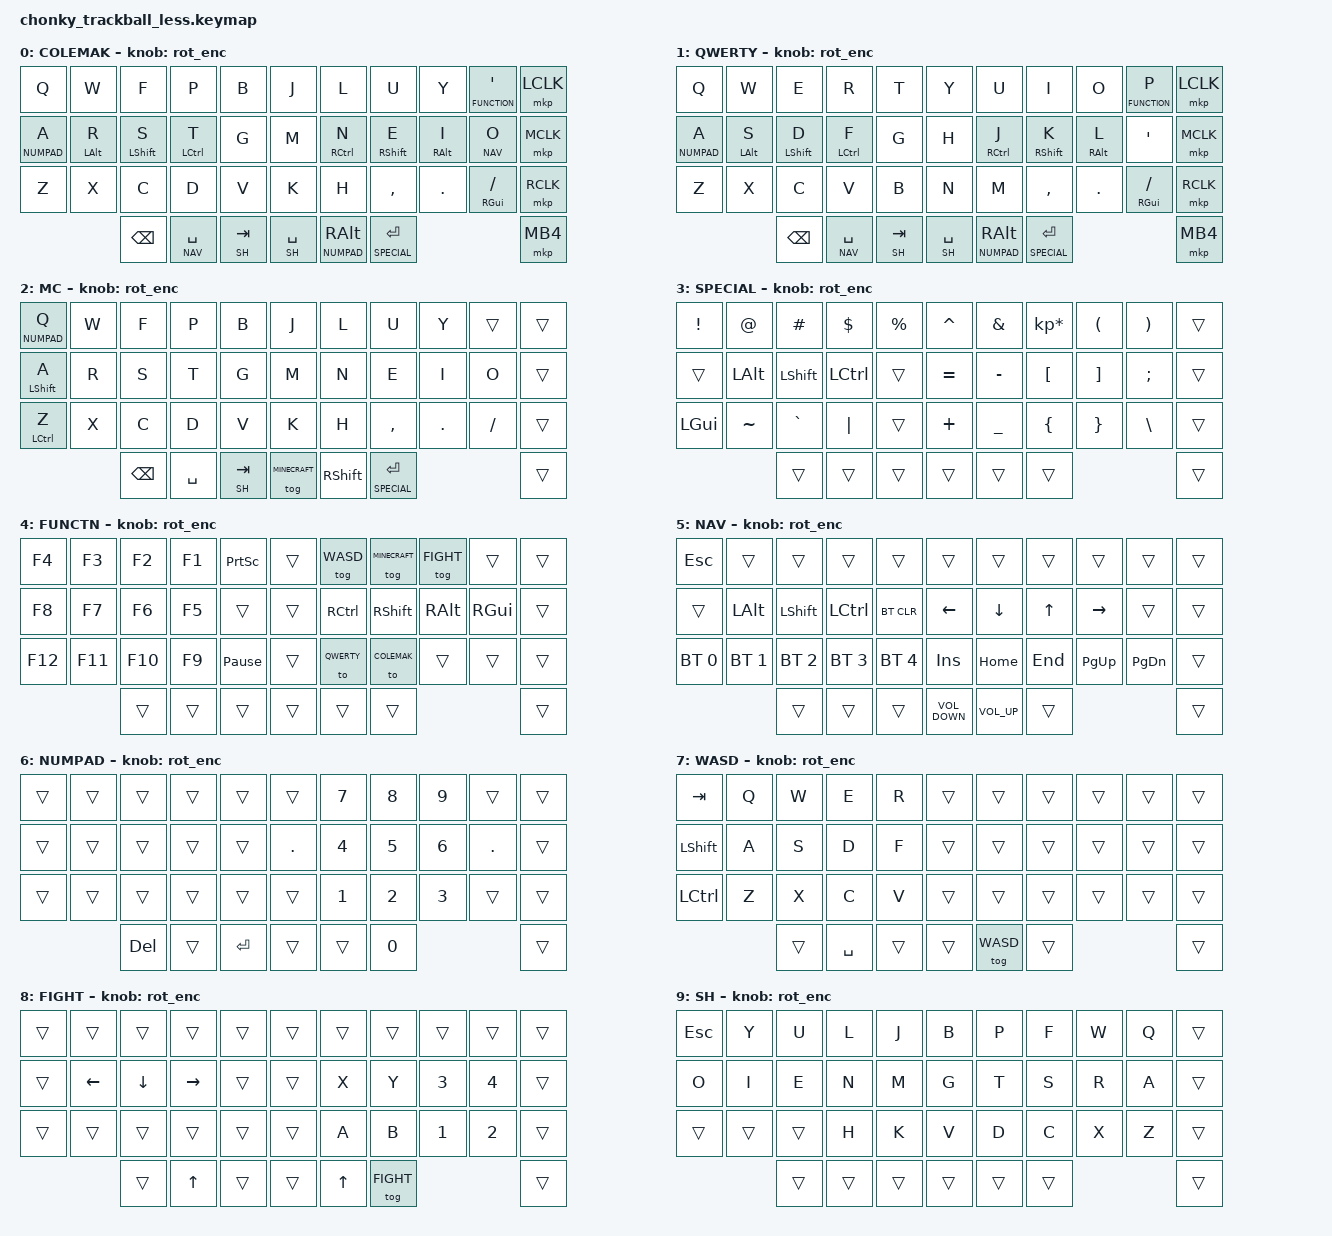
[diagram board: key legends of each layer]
 /*
 * Copyright (c) 2020 The ZMK Contributors
 *
 * SPDX-License-Identifier: MIT
 */


#include <zephyr/dt-bindings/input/input-event-codes.h>

#include <behaviors.dtsi>
#include <behaviors/mouse_keys.dtsi>
#include <behaviors/mouse_key_press.dtsi>
#include <dt-bindings/zmk/keys.h>
#include <dt-bindings/zmk/bt.h>
#include <dt-bindings/zmk/mouse.h>
#include <dt-bindings/zmk/input_transform.h>

#define COLEMAK 0
#define QWERTY 1
#define MINECRAFT 2
#define SPECIAL 3
#define FUNCTION 4
#define NAV 5
#define NUMPAD 6
#define WASD 7
#define FIGHT 8
#define SH 9

&caps_word {
        continue-list = <UNDERSCORE MINUS>;
};

/ {
        xy_transf: xy_transf {
                compatible = "zmk,input-processor-transform";
                #input-processor-cells = <1>;
                type = <INPUT_EV_REL>;
                x-codes = <INPUT_REL_X>, <INPUT_REL_WHEEL>;
                y-codes = <INPUT_REL_Y>, <INPUT_REL_HWHEEL>;
        };
        xy_scaler: xy_scaler {
                compatible = "zmk,input-processor-scaler";
                #input-processor-cells = <2>;
                type = <INPUT_EV_REL>;
                codes = <INPUT_REL_X>, <INPUT_REL_Y>;
                track-remainders;
        };
        x_scaler: x_scaler {
                compatible = "zmk,input-processor-scaler";
                #input-processor-cells = <2>;
                type = <INPUT_EV_REL>;
                codes = <INPUT_REL_X>;
        };
        to_wheel: to_wheel {
                compatible = "zmk,input-processor-code-mapper";
                #input-processor-cells = <0>;
                type = <INPUT_EV_REL>;
                map = <INPUT_REL_X INPUT_REL_MISC>, <INPUT_REL_Y INPUT_REL_WHEEL>;
        };

        //mou0_mmv_il {
        //        compatible = "zmk,input-listener";
        //        device = <&pd>;
        //        input-processors = <&xy_transf (INPUT_TRANSFORM_X_INVERT | INPUT_TRANSFORM_Y_INVERT)>;
        //};

        behaviors {
                combos {
                        compatible = "zmk,combos";
                        combo_caps_word {
                                timeout-ms = <50>;
                                key-positions = <26 27>;
                                bindings = <&caps_word>;
                        };
                };
                lh_ctrl: left_hand_control {
                        compatible = "zmk,behavior-hold-tap";
                        label = "POSITIONAL_HOLD_TAP_LEFT_CONTROL";
                        #binding-cells = <2>;
                        flavor = "balanced";
                        tapping-term-ms = <250>;
                        quick-tap-ms = <300>;
                        bindings = <&kp>, <&kp>;
                        #hold-trigger-key-positions = <1 2 3 12 13 14 15 19 25 26>;
                };
                rh_ctrl: right_hand_control {
                        compatible = "zmk,behavior-hold-tap";
                        label = "POSITIONAL_HOLD_TAP_RIGHT_CONTROL";
                        #binding-cells = <2>;
                        flavor = "balanced";
                        tapping-term-ms = <250>;
                        quick-tap-ms = <300>;
                        bindings = <&kp>, <&kp>;
                        #hold-trigger-key-positions = <3 4 13 14 16 17 25 26 27 29>;
                };
                lh_alt: left_hand_alt {
                        compatible = "zmk,behavior-hold-tap";
                        label = "POSITIONAL_HOLD_TAP_LEFT_ALT";
                        #binding-cells = <2>;
                        flavor = "balanced";
                        tapping-term-ms = <250>;
                        quick-tap-ms = <300>;
                        bindings = <&kp>, <&kp>;
                        #hold-trigger-key-positions = <12 28>;
                };
                rh_alt: right_hand_alt {
                        compatible = "zmk,behavior-hold-tap";
                        label = "POSITIONAL_HOLD_TAP_RIGHT_ALT";
                        #binding-cells = <2>;
                        flavor = "balanced";
                        tapping-term-ms = <250>;
                        quick-tap-ms = <300>;
                        bindings = <&kp>, <&kp>;
                        hold-trigger-key-positions = <12 28>;
                };
                lh_shft: left_hand_shift {
                        compatible = "zmk,behavior-hold-tap";
                        label = "POSITIONAL_HOLD_TAP_LEFT_SHIFT";
                        #binding-cells = <2>;
                        flavor = "balanced";
                        tapping-term-ms = <175>;
                        quick-tap-ms = <300>;
                        bindings = <&kp>, <&kp>;
                };
                rh_shft: right_hand_shift {
                        compatible = "zmk,behavior-hold-tap";
                        label = "POSITIONAL_HOLD_TAP_RIGHT_SHIFT";
                        #binding-cells = <2>;
                        flavor = "balanced";
                        tapping-term-ms = <175>;
                        quick-tap-ms = <300>;
                        bindings = <&kp>, <&kp>;
                };
                lh_num: left_hand_numpad {
                        compatible = "zmk,behavior-hold-tap";
                        label = "POSITIONAL_HOLD_TAP_LEFT_GUI";
                        #binding-cells = <2>;
                        flavor = "balanced";
                        tapping-term-ms = <200>;
                        quick-tap-ms = <300>;
                        bindings = <&kp>, <&kp>;
                };
                rh_gui: right_hand_gui {
                        compatible = "zmk,behavior-hold-tap";
                        label = "POSITIONAL_HOLD_TAP_RIGHT_GUI";
                        #binding-cells = <2>;
                        flavor = "balanced";
                        tapping-term-ms = <250>;
                        quick-tap-ms = <300>;
                        bindings = <&kp>, <&kp>;
                        #hold-trigger-key-positions = <7 12 14>;
                };
                spc_nav: space_navigation {
                        compatible = "zmk,behavior-hold-tap";
                        label = "POSITIONAL_HOLD_TAP_SPACE_NAV";
                        #binding-cells = <2>;
                        flavor = "balanced";
                        tapping-term-ms = <200>;
                        quick-tap-ms = <100>;
                        bindings = <&kp>, <&kp>;
                };
                spc_ret: special_return {
                        compatible = "zmk,behavior-hold-tap";
                        label = "POSITIONAL_HOLD_TAP_SPECIAL_RET";
                        #binding-cells = <2>;
                        flavor = "balanced";
                        tapping-term-ms = <175>;
                        quick-tap-ms = <100>;
                        bindings = <&kp>, <&kp>;
                };
                ec_s: mouse_scroll {
                        compatible = "zmk,behavior-input-two-axis";
                        #binding-cells = <1>;
                        trigger-period-ms = <12>; // slow down for OTA, default is 3ms
                        x-input-code = <INPUT_REL_HWHEEL>;
                        y-input-code = <INPUT_REL_WHEEL>;
                        time-to-max-speed-ms = <177>;
                        acceleration-exponent = <0>;
                };
                rot_enc: rot_enc {
                        compatible = "zmk,behavior-sensor-rotate";
                        #sensor-binding-cells = <0>;
                        bindings = <&ec_s MOVE_Y(-37)>, <&ec_s MOVE_Y(37)>;
                        //bindings = <&msc SCRL_UP>, <&msc SCRL_DOWN>;
                        //bindings = <&kp X>, <&msc SCRL_DOWN>;
                        tap-ms = <65>;
                };

        };
        keymap {
                compatible = "zmk,keymap";

                default_layer {
                        display-name = "COLEMAK";
// |-------------------------------------------------------------------------| |------------------------------------------------------------------------------| |--------|//
// | Q           | W            | F              | P              | B        | | J           | L               | U              | Y            | '"           | | LClick |//
// | A-NUM       | R-alt        | S-shift        | T-ctrl         | G        | | M           | N-ctrl          | E-shift        | I-alt        | O            | | MClick |//
// | Z           | X            | C              | D              | V        | | K           | H               | ,<             | .>           | /?gui        | | RClick |//
// |                            \ BACKSPACE      | SPC (nav)      | TAB-SH   | | SPACE-SH    | RALT-NUM        | ENT (special)  /                             | | Back   |//
// |=========================================================================| |==============================================================================| |--------|//
                        bindings = <
    &kp Q        &kp W          &kp F            &kp P            &kp B         &kp J        &kp L            &kp U            &kp Y          &lt FUNCTION SQT   &mkp LCLK
    &lt NUMPAD A &lh_alt LALT R &lh_shft LSHFT S &lh_ctrl LCTRL T &kp G         &kp M        &rh_ctrl RCTRL N &rh_shft RSHFT E &rh_alt RALT I &lt NAV O          &mkp MCLK
    &kp Z        &kp X          &kp C            &kp D            &kp V         &kp K        &kp H            &kp COMMA        &kp DOT        &rh_gui RGUI FSLH  &mkp RCLK
                                &kp BKSP         &lt NAV SPACE    &lt SH TAB    &lt SH SPACE &lt NUMPAD RALT  &lt SPECIAL RET                                    &mkp MB4
                        >;
                        sensor-bindings = <&rot_enc>;
                };

                qwerty_layer {
                        display-name = "QWERTY";
// |-------------------------------------------------------------------------| |------------------------------------------------------------------------------| |--------|//
// | Q           | W            | E              | R              | T        | | Y           | U              | I              | O            | P             | | LClick |//
// | A-NUM       | S-alt        | D-shift        | F-ctrl         | G        | | H           | J-ctrl         | K-shift        | L-alt        | ;:            | | MClick |//
// | Z           | X            | C              | V              | B        | | N           | M              | ,<             | .>           | /?gui         | | RClick |//
// |                            \ BACKSPACE      | SPC (nav)      | TAB      | |             |                | ENT (special)  /                              | | Back   |//
// |=========================================================================| |==============================================================================| |--------|//
                        bindings = <
    &kp Q        &kp W          &kp E            &kp R            &kp T         &kp Y        &kp U            &kp I            &kp O          &lt FUNCTION P     &mkp LCLK
    &lt NUMPAD A &lh_alt LALT S &lh_shft LSHFT D &lh_ctrl LCTRL F &kp G         &kp H        &rh_ctrl RCTRL J &rh_shft RSHFT K &rh_alt RALT L &kp SQT            &mkp MCLK
    &kp Z        &kp X          &kp C            &kp V            &kp B         &kp N        &kp M            &kp COMMA        &kp DOT        &rh_gui RGUI FSLH  &mkp RCLK
                                &kp BKSP         &lt NAV SPACE    &lt SH TAB    &lt SH SPACE &lt NUMPAD RALT  &lt SPECIAL RET                                    &mkp MB4
                        >;
                        sensor-bindings = <&rot_enc>;
                };

                minecraft_layer {
                        display-name = "MC";
// |----------------------------------------------------//-------------------------------------------------| //
// |    TAB    |   Q   |    W   |     E     |   R   |   //   |       |           |       |        |        | //
// |    LSHT   |   A   |    S   |     D     |   F   |   //   |       |           |       |        |        | //
// |    LCTL   |   Z   |    X   |     C     |   V   |   //   |       |           |       |        |        | //
// |                   \        |           |       |   //   |       |    WASD   |       /                 | //
// |====================================================//=================================================| //
                        bindings = <
    &lt NUMPAD Q            &kp W          &kp F            &kp P            &kp B         &kp J          &kp L         &kp U            &kp Y          &trans             &trans
    &lh_shft LSHFT A       &kp R          &kp S            &kp T            &kp G         &kp M          &kp N         &kp E            &kp I          &kp O              &trans
    &lh_ctrl LCTRL Z        &kp X          &kp C            &kp D            &kp V         &kp K          &kp H         &kp COMMA        &kp DOT        &kp FSLH           &trans
                                           &kp BKSP         &kp SPACE        &lt SH TAB    &tog MINECRAFT &kp RSHIFT    &lt SPECIAL RET                                    &trans
                        >;
                        sensor-bindings = <&rot_enc>;
                };

                special_layer {
                        display-name = "SPECIAL";
// |-------------------------------------------------------------//--------------------------------------------------------------------| //
// |     !    |    @      |    #     |    $     |   %       |    //    |     ^     |     &     |        *        |     (    |     )    | //
// |          |    alt    |    shft  |    ctrl  |           |    //    |     =     |     -     |        [        |     ]    |     ;    | //
// |    gui   |    ~      |    `     |    |     |           |    //    |     +     |     _     |        {        |     }    |     \    | //
// |                      \          |          |           |    //    |           |           |                 /                     | //
// |=============================================================//====================================================================| //
                        bindings = <
     &kp EXCL   &kp AT     &kp HASH    &kp DLLR   &kp PRCNT              &kp CARET   &kp AMPS    &kp KP_MULTIPLY   &kp LPAR   &kp RPAR  &trans
     &trans     &kp LALT   &kp LSHFT   &kp LCTL   &trans                 &kp EQUAL   &kp MINUS   &kp LBKT          &kp RBKT   &kp SEMI  &trans
     &kp LGUI   &kp TILDE  &kp GRAVE   &kp PIPE   &trans                 &kp PLUS    &kp UNDER   &kp LBRC          &kp RBRC   &kp BSLH  &trans
                           &trans      &trans     &trans                 &trans      &trans      &trans                                 &trans
                        >;
                        sensor-bindings = <&rot_enc>;
                };

                function_layer {
                        display-name = "FUNCTN";
// |----------------------------------------------------------//------------------------------------------------------------| //
// |   F4    |   F3   |   F2    |   F1   | Prnt SCR       |   //   |       |    WASD   | MINECRAFT  |    FIGHT   |          | //
// |   F8    |   F7   |   F6    |   F5   |                |   //   |       |    ctrl   |    shft    |    alt     |    gui   | //
// |   F12   |   F11  |   F10   |   F9   |                |   //   |       |  QWERTY   |  COLEMAK   |            |          | //
// |                  \         |        | Pause Break    |   //   |       |           |            /                       | //
// |==========================================================//============================================================| //
                        bindings = <
     &kp F4    &kp F3   &kp F2    &kp F1  &kp PSCRN                  &trans  &tog WASD   &tog MINECRAFT &tog FIGHT   &trans    &trans
     &kp F8    &kp F7   &kp F6    &kp F5  &trans                     &trans  &kp RCTRL   &kp RSHFT      &kp RALT     &kp RGUI  &trans
     &kp F12   &kp F11  &kp F10   &kp F9  &kp PAUSE_BREAK            &trans  &to QWERTY  &to COLEMAK    &trans       &trans    &trans
                        &trans    &trans  &trans                     &trans  &trans      &trans                                &trans
                        >;
                        sensor-bindings = <&rot_enc>;
                };

                navigation_layer {
                        display-name = "NAV";
// |-------------------------------------------------------------------------------//--------------------------------------------------------------------------| //
// |     ESC      |              |              |              |               |   //   |                   |                |          |           |          | //
// |              |      LALT    |     LSHFT    |     LCTRL    |     BTCLR     |   //   |     LFT           |    DWN         |    UP    |   RGT     |          | //
// |     BT1      |      BT2     |     BT3      |     BT4      |     BT5       |   //   |     PG INS        |    HOME        |    END   |   PG UP   |   PG DN  | //
// |                             \              |              |               |   //   |     VOLUME DOWN   |    VOLUME UP   |          /                      | //
// |===============================================================================//==========================================================================| //
                        bindings = <
     &kp ESC        &trans         &trans         &trans          &trans                  &trans              &trans           &trans     &trans      &trans    &trans
     &trans         &kp LALT       &kp LSHFT      &kp LCTRL       &bt BT_CLR              &kp LEFT            &kp DOWN         &kp UP     &kp RIGHT   &trans    &trans
     &bt BT_SEL 0   &bt BT_SEL 1   &bt BT_SEL 2   &bt BT_SEL 3    &bt BT_SEL 4            &kp INS             &kp HOME         &kp END    &kp PG_UP   &kp PG_DN &trans
                                   &trans         &trans          &trans                  &kp K_VOLUME_DOWN   &kp K_VOLUME_UP  &trans                           &trans
                        >;
                        sensor-bindings = <&rot_enc>;
                };

                numpad_layer {
                        display-name = "NUMPAD";
// |--------------------------------------------------//------------------------------------------------| //
// |        |        |         |        |         |   //   |        |    7   |    8   |    9   |        | //
// |        |        |         |        |         |   //   |    .   |    4   |    5   |    6   |    .   | //
// |        |        |         |        |         |   //   |        |    1   |    2   |    3   |        | //
// |                 \   DEL   |        |  ENTER  |   //   |        |        |    0   /                 | //
// |==================================================//================================================| //
                        bindings = <
     &trans   &trans   &trans    &trans   &trans            &trans    &kp N7   &kp N8   &kp N9  &trans  &trans
     &trans   &trans   &trans    &trans   &trans            &kp DOT   &kp N4   &kp N5   &kp N6  &kp DOT &trans
     &trans   &trans   &trans    &trans   &trans            &trans    &kp N1   &kp N2   &kp N3  &trans  &trans
                       &kp DEL   &trans   &kp RET           &trans    &trans   &kp N0                   &trans
                        >;
                        sensor-bindings = <&rot_enc>;
                };

                wasd_layer {
                        display-name = "WASD";
// |----------------------------------------------------//-------------------------------------------------| //
// |    TAB    |   Q   |    W   |     E     |   R   |   //   |       |           |       |        |        | //
// |    LSHT   |   A   |    S   |     D     |   F   |   //   |       |           |       |        |        | //
// |    LCTL   |   Z   |    X   |     C     |   V   |   //   |       |           |       |        |        | //
// |                   \        |           |       |   //   |       |    WASD   |       /                 | //
// |====================================================//=================================================| //
                        bindings = <
     &kp TAB     &kp Q   &kp W    &kp E      &kp R            &trans   &trans     &trans   &trans   &trans      &trans
     &kp LSHIFT  &kp A   &kp S    &kp D      &kp F            &trans   &trans     &trans   &trans   &trans      &trans
     &kp LCTRL   &kp Z   &kp X    &kp C      &kp V            &trans   &trans     &trans   &trans   &trans      &trans
                         &trans   &kp SPACE  &trans           &trans   &tog WASD  &trans                        &trans
                        >;
                        sensor-bindings = <&rot_enc>;
                };

                fightstick_layer {
                        display-name = "FIGHT";
// |-------------------------------------------------//--------------------------------------------------| //
// |       |         |         |         |       |   //   |      |         |           |        |        | //
// |       |   LFT   |   DWN   |   RGT   |       |   //   |      |    X    |     Y     |    3   |    4   | //
// |       |         |         |         |       |   //   |      |    A    |     B     |    1   |    2   | //
// |                 \         |   UP    |       |   //   |      |    UP   |   FIGHT   /                 | //
// |=================================================//==================================================| //
                        bindings = <
    &trans  &trans    &trans    &trans     &trans          &trans   &trans   &trans      &trans   &trans        &trans
    &trans  &kp LEFT  &kp DOWN  &kp RIGHT  &trans          &trans   &kp X    &kp Y       &kp N3   &kp N4        &trans
    &trans  &trans    &trans    &trans     &trans          &trans   &kp A    &kp B       &kp N1   &kp N2        &trans
                      &trans    &kp UP     &trans          &trans   &kp UP   &tog FIGHT                         &trans
                        >;
                        sensor-bindings = <&rot_enc>;
                };

                single_hand_layer {
                        display-name = "SH";
// |--------------------------------------------------//---------------------------------------------------| //
// |  ESC  |     Y    |    U    |    L    |   J   |   //   |   B  |    P    |    F      |   W    |   Q     | //
// |   O   |     I    |    E    |    N    |   M   |   //   |   G  |    T    |    S      |   R    |   A     | //
// |       |          |         |    H    |   K   |   //   |   V  |    D    |    C      |   X    |   Z     | //
// |                  \         |         |       |   //   |      |         |           /                  | //
// |==================================================//===================================================| //
                        bindings = <
    &kp ESC     &kp Y     &kp U     &kp L      &kp J         &kp B    &kp P    &kp F       &kp W    &kp Q       &trans
    &kp O       &kp I     &kp E     &kp N      &kp M         &kp G    &kp T    &kp S       &kp R    &kp A       &trans
    &trans      &trans    &trans    &kp H      &kp K         &kp V    &kp D    &kp C       &kp X    &kp Z       &trans
                          &trans    &trans     &trans        &trans   &trans   &trans                           &trans
                        >;
                        sensor-bindings = <&rot_enc>;
                };

        };
};
